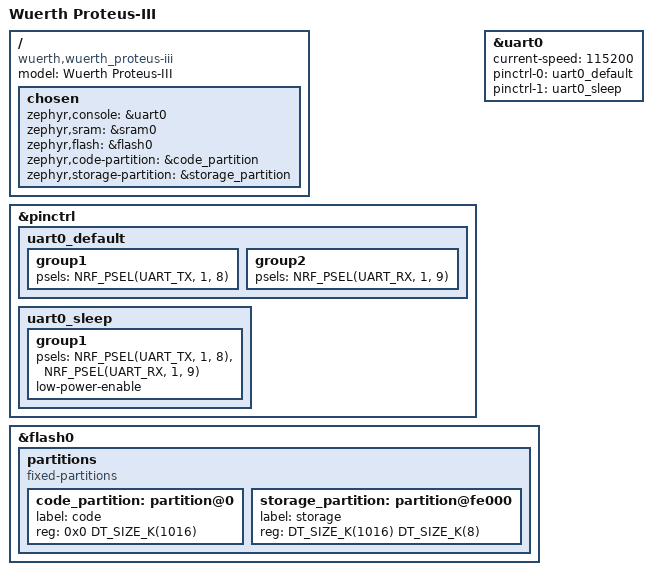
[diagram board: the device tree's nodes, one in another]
// Copyright (c) 2021 Nordic Semiconductor ASA
// SPDX-License-Identifier: Apache-2.0

/dts-v1/;
#include <nordic/nrf52840_qiaa.dtsi>

/ {
	model = "Wuerth Proteus-III";
	compatible = "wuerth,wuerth_proteus-iii";

	chosen {
		zephyr,console = &uart0;
		zephyr,sram = &sram0;
		zephyr,flash = &flash0;
		zephyr,code-partition = &code_partition;
		zephyr,storage-partition = &storage_partition;
	};
};

&pinctrl {
	uart0_default: uart0_default {
		group1 {
			psels = <NRF_PSEL(UART_TX, 1, 8)>;
		};
		group2 {
			psels = <NRF_PSEL(UART_RX, 1, 9)>;
		};
	};
	uart0_sleep: uart0_sleep {
		group1 {
			psels = <NRF_PSEL(UART_TX, 1, 8)>,
					<NRF_PSEL(UART_RX, 1, 9)>;
			low-power-enable;
		};
	};
};

&uart0 {
	current-speed = <115200>;
	status = "okay";
	pinctrl-0 = <&uart0_default>;
	pinctrl-1 = <&uart0_sleep>;
	pinctrl-names = "default", "sleep";
	// tx-pin = <40>;
	// rx-pin = <41>;
};

&flash0 {
	partitions {
		compatible = "fixed-partitions";
		#address-cells = <1>;
		#size-cells = <1>;

		code_partition: partition@0 {
			label = "code";
			reg = <0x0 DT_SIZE_K(1016)>;
		};
		storage_partition: partition@fe000 {
			label = "storage";
			reg = <DT_SIZE_K(1016) DT_SIZE_K(8)>;
		};
	};
};
